VERSION ""

NS_ :

BS_:

BU_: ECU Motor PowerAux Solar MotorController

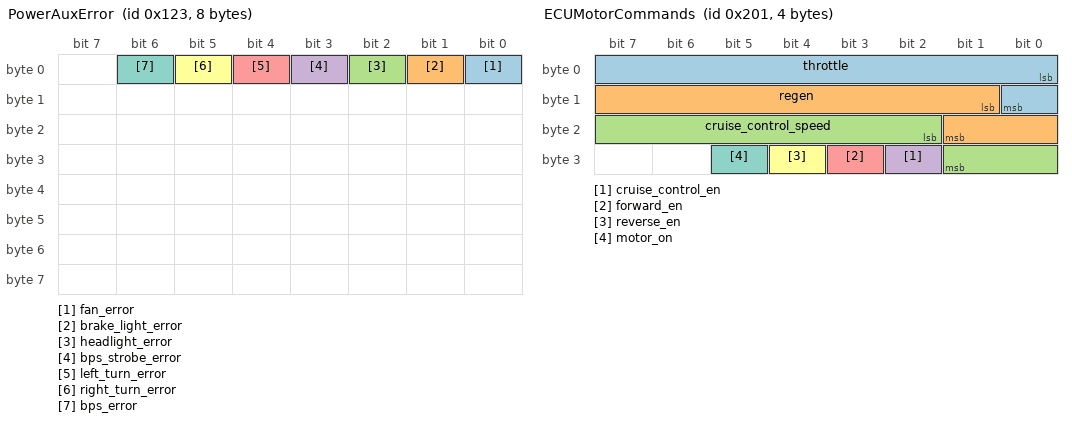
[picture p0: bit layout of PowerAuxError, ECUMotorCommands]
BO_ 291 PowerAuxError: 8 PowerAux
 SG_ fan_error : 0|1@1+ (1,0) [0|0] "" Vector__XXX
 SG_ brake_light_error : 1|1@1+ (1,0) [0|0] "" Vector__XXX
 SG_ headlight_error : 2|1@1+ (1,0) [0|0] "" Vector__XXX
 SG_ bps_strobe_error : 3|1@1+ (1,0) [0|0] "" Vector__XXX
 SG_ left_turn_error : 4|1@1+ (1,0) [0|0] "" Vector__XXX
 SG_ right_turn_error : 5|1@1+ (1,0) [0|0] "" Vector__XXX
 SG_ bps_error : 6|1@1+ (1,0) [0|0] "" Vector__XXX

BO_ 513 ECUMotorCommands: 4 ECU
 SG_ throttle : 0|9@1+ (1,0) [0|256] "" Vector__XXX
 SG_ regen : 9|9@1+ (1,0) [0|256] "" Vector__XXX
 SG_ cruise_control_speed : 18|8@1+ (1,0) [0|0] "" Vector__XXX
 SG_ cruise_control_en : 26|1@1+ (1,0) [0|0] "" Vector__XXX
 SG_ forward_en : 27|1@1+ (1,0) [0|0] "" Vector__XXX
 SG_ reverse_en : 28|1@1+ (1,0) [0|0] "" Vector__XXX
 SG_ motor_on : 29|1@1+ (1,0) [0|0] "" Vector__XXX

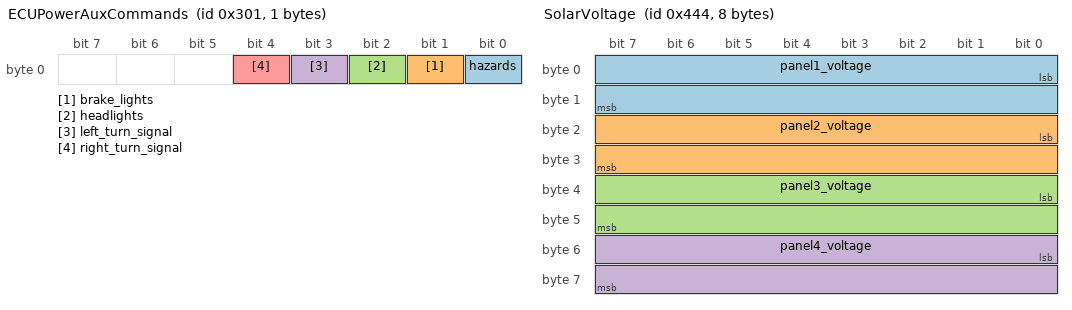
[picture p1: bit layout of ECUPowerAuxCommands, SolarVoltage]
BO_ 769 ECUPowerAuxCommands: 1 ECU
 SG_ hazards : 0|1@1+ (1,0) [0|0] "" Vector__XXX
 SG_ brake_lights : 1|1@1+ (1,0) [0|0] "" Vector__XXX
 SG_ headlights : 2|1@1+ (1,0) [0|0] "" Vector__XXX
 SG_ left_turn_signal : 3|1@1+ (1,0) [0|0] "" Vector__XXX
 SG_ right_turn_signal : 4|1@1+ (1,0) [0|0] "" Vector__XXX

BO_ 1076 SolarCurrent: 2 Solar
 SG_ total_current : 0|16@1+ (1,0) [0|0] "" Vector__XXX

BO_ 1092 SolarVoltage: 8 Solar
 SG_ panel1_voltage : 0|16@1+ (1,0) [0|0] "" Vector__XXX
 SG_ panel2_voltage : 16|16@1+ (1,0) [0|0] "" Vector__XXX
 SG_ panel3_voltage : 32|16@1+ (1,0) [0|0] "" Vector__XXX
 SG_ panel4_voltage : 48|16@1+ (1,0) [0|0] "" Vector__XXX

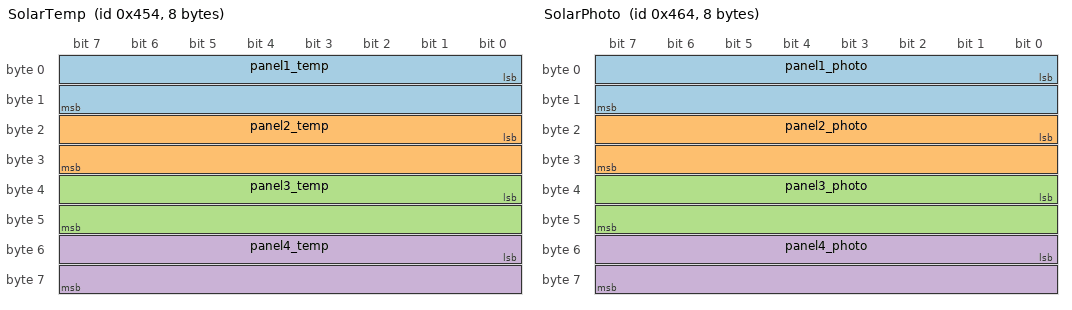
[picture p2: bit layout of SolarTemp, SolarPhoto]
BO_ 1108 SolarTemp: 8 Solar
 SG_ panel1_temp : 0|16@1+ (1,0) [0|0] "" Vector__XXX
 SG_ panel2_temp : 16|16@1+ (1,0) [0|0] "" Vector__XXX
 SG_ panel3_temp : 32|16@1+ (1,0) [0|0] "" Vector__XXX
 SG_ panel4_temp : 48|16@1+ (1,0) [0|0] "" Vector__XXX

BO_ 1124 SolarPhoto: 8 Solar
 SG_ panel1_photo : 0|16@1+ (1,0) [0|0] "" Vector__XXX
 SG_ panel2_photo : 16|16@1+ (1,0) [0|0] "" Vector__XXX
 SG_ panel3_photo : 32|16@1+ (1,0) [0|0] "" Vector__XXX
 SG_ panel4_photo : 48|16@1+ (1,0) [0|0] "" Vector__XXX

BA_DEF_  "BusType" STRING ;
BA_DEF_DEF_  "BusType" "CAN";
